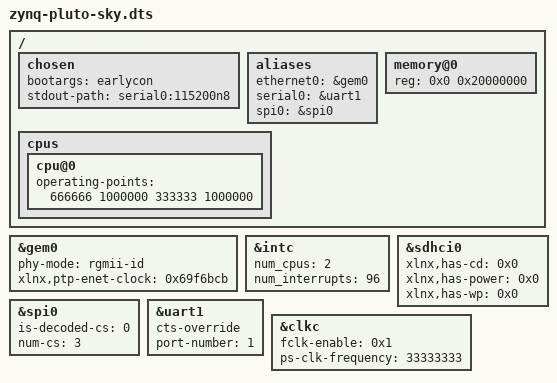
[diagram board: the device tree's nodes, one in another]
/*
 * PlutoSKY board
 * hdl_project: <PlutoSKY/pluto_sky_ps_wrapper>
 *
 * Generated from pluto_sky_ps_wrapper.xsa (Vivado 2022.1). The design
 * is a bare processing_system7 wrapper - no PL IP is instantiated, so
 * this dts only covers the PS peripherals enabled in the block design:
 * gem0 (RGMII, MDIO), sdhci0, qspi, uart1 and spi0 (routed via EMIO to
 * top-level FPGA pins, presumably for a companion RF front-end - the
 * spi0 node itself needs no MIO-specific properties either way).
 *
 * UART0 is disabled in the block design (MIO not muxed for it) - only
 * UART1 (MIO 8/9) is wired up, so it is the console here.
 */

/dts-v1/;
#include "zynq-7000.dtsi"

/ {
	chosen {
		bootargs = "earlycon";
		stdout-path = "serial0:115200n8";
	};
	aliases {
		ethernet0 = &gem0;
		serial0 = &uart1;
		spi0 = &spi0;
	};
	memory@0 {
		device_type = "memory";
		reg = <0x0 0x20000000>;
	};

	cpus {
		cpu@0 {
			operating-points = <666666 1000000 333333 1000000>;
		};
	};
};

&gem0 {
	phy-mode = "rgmii-id";
	status = "okay";
	xlnx,ptp-enet-clock = <0x69f6bcb>;
};
&intc {
	num_cpus = <2>;
	num_interrupts = <96>;
};
&sdhci0 {
	bootph-all;
	status = "okay";
	xlnx,has-cd = <0x0>;
	xlnx,has-power = <0x0>;
	xlnx,has-wp = <0x0>;
};
&spi0 {
	is-decoded-cs = <0>;
	num-cs = <3>;
	status = "okay";
};
&uart1 {
	bootph-all;
	cts-override ;
	device_type = "serial";
	port-number = <1>;
	status = "okay";
};
&clkc {
	fclk-enable = <0x1>;
	ps-clk-frequency = <33333333>;
};
